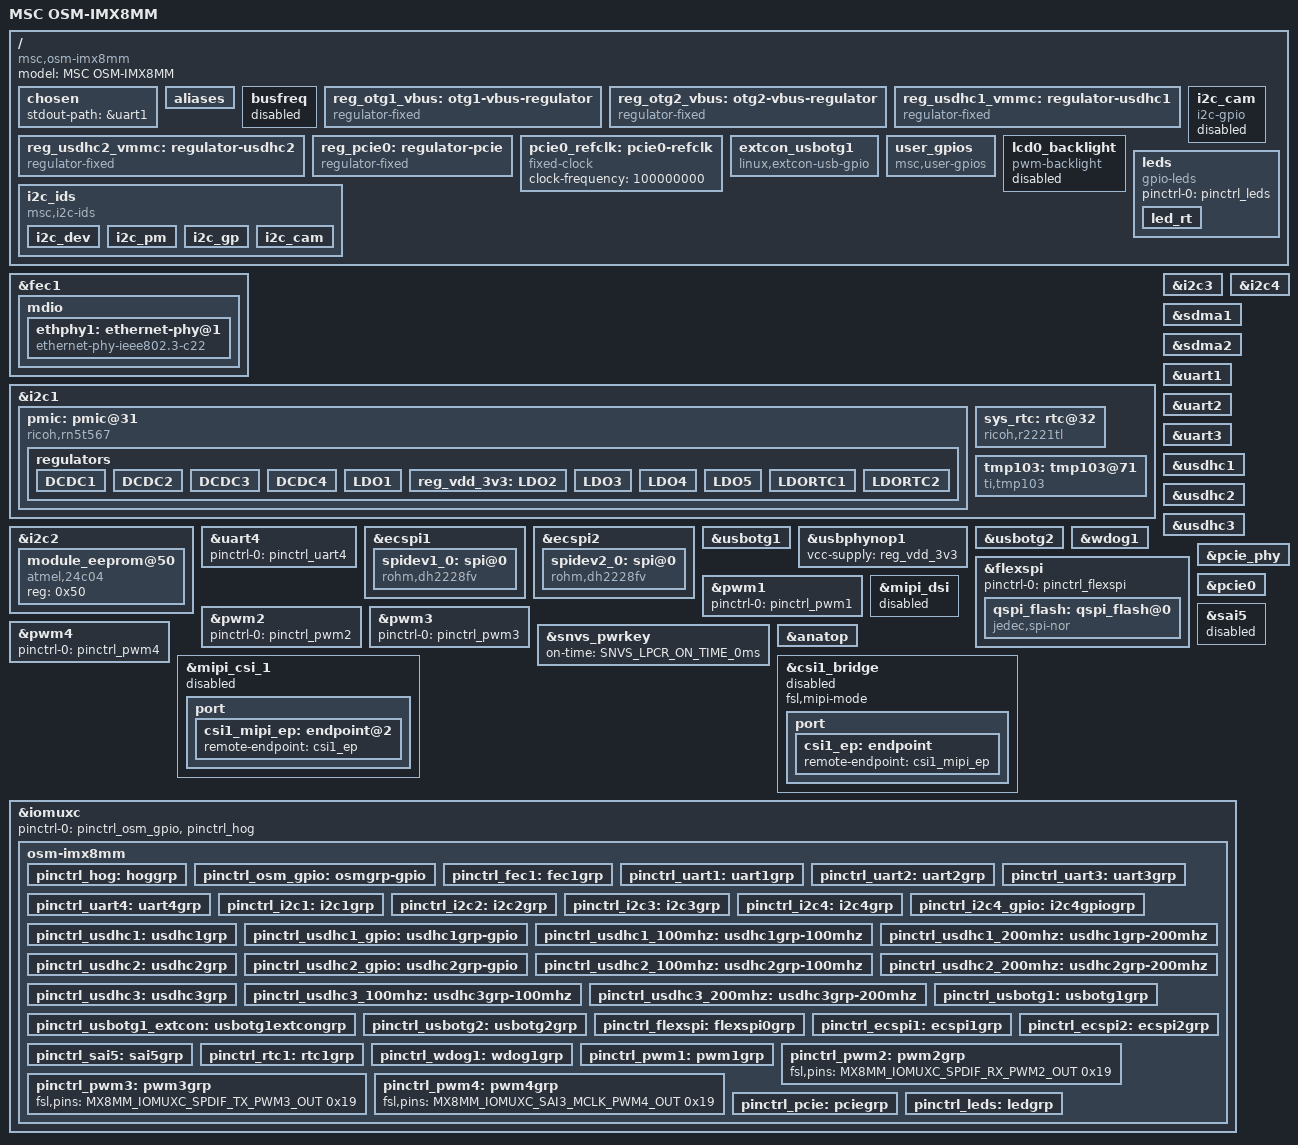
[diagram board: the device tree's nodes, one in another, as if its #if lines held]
/*
 * Copyright (C) 2022 Avnet Embedded GmbH
 *
 * This program is free software; you can redistribute it and/or
 * modify it under the terms of the GNU General Public License as
 * published by the Free Software Foundation version 2.
 *
 * This program is distributed "as is" WITHOUT ANY WARRANTY of any
 * kind, whether express or implied; without even the implied warranty
 * of MERCHANTABILITY or FITNESS FOR A PARTICULAR PURPOSE.  See the
 * GNU General Public License for more details.
 */

#include <dt-bindings/usb/pd.h>
#include "../../freescale/imx8mm.dtsi"
#include "dt-bindings/phy/phy-imx8-pcie.h"
#include <dt-bindings/net/ti-dp83867.h>
#include <dt-bindings/mfd/ricoh-rn5t618.h>
#include <dt-bindings/input/snvs_pwrkey.h>
#include <dt-bindings/thermal/thermal.h>

/ {
	model = "MSC OSM-IMX8MM";
	compatible = "msc,osm-imx8mm", "fsl,imx8mm";

	chosen {
		stdout-path = &uart1;
	};

	aliases {
		rtc0 = &sys_rtc;
		rtc1 = &snvs_rtc;
		ser0 = &uart1;
		ser1 = &uart3;
		ser2 = &uart2;
		ser3 = &uart4;
		i2c-dev = &i2c1;
		i2c-pm = &i2c2;
		i2c-gp = &i2c3;
		i2c-cam = &i2c4;
	};

	busfreq {
		status = "disabled";
	};

	reg_otg1_vbus: otg1-vbus-regulator {
		compatible = "regulator-fixed";
		regulator-name = "OTG1_VBUS";
		regulator-min-microvolt = <1800000>;
		regulator-max-microvolt = <1800000>;
		gpio = <&gpio1 12 GPIO_ACTIVE_HIGH>;
		enable-active-high;
		regulator-always-on;
	};

	reg_otg2_vbus: otg2-vbus-regulator {
		compatible = "regulator-fixed";
		regulator-name = "OTG2_VBUS";
		regulator-min-microvolt = <1800000>;
		regulator-max-microvolt = <1800000>;
		gpio = <&gpio1 14 GPIO_ACTIVE_HIGH>;
		enable-active-high;
		regulator-always-on;
	};

	reg_usdhc1_vmmc: regulator-usdhc1 {
		compatible = "regulator-fixed";
		regulator-name = "VSD1_3V3";
		regulator-min-microvolt = <3300000>;
		regulator-max-microvolt = <3300000>;
		gpio = <&gpio2 10 GPIO_ACTIVE_HIGH>;
		enable-active-high;
		startup-delay-us = <100>;
		u-boot,off-on-delay-us = <12000>;
	};

	reg_usdhc2_vmmc: regulator-usdhc2 {
		compatible = "regulator-fixed";
		regulator-name = "VSD2_3V3";
		regulator-min-microvolt = <3300000>;
		regulator-max-microvolt = <3300000>;
		gpio = <&gpio2 19 GPIO_ACTIVE_HIGH>;
		enable-active-high;
		startup-delay-us = <100>;
		u-boot,off-on-delay-us = <12000>;
	};

	reg_pcie0: regulator-pcie {
		compatible = "regulator-fixed";
		regulator-name = "PCIE_3V3";
		regulator-min-microvolt = <3300000>;
		regulator-max-microvolt = <3300000>;
		regulator-always-on;
	};

	pcie0_refclk: pcie0-refclk {
		compatible = "fixed-clock";
		#clock-cells = <0>;
		clock-frequency = <100000000>;
	};

	i2c_cam: i2c_cam {
		pinctrl-names = "default";
		pinctrl-0 = <&pinctrl_i2c4>, <&pinctrl_i2c4_gpio>;
		compatible = "i2c-gpio";
		#address-cells = <1>;
		#size-cells = <0>;
		sda-gpios = <&gpio5 21 (GPIO_ACTIVE_HIGH | GPIO_OPEN_DRAIN)>;
		scl-gpios = <&gpio5 20 (GPIO_ACTIVE_HIGH | GPIO_OPEN_DRAIN)>;
		i2c-gpio,delay-us = <2>;	/* ~100 kHz */
		status = "disabled";
	};

	extcon_usbotg1: extcon_usbotg1 {
		pinctrl-names = "default";
		pinctrl-0 = <&pinctrl_usbotg1_extcon>;
		compatible = "linux,extcon-usb-gpio";
		id-gpio = <&gpio1 10 GPIO_ACTIVE_HIGH>;
	};

	user_gpios {
		compatible = "msc,user-gpios";
		GPIO_A0-gpios = <&gpio4 25 GPIO_ACTIVE_HIGH>;
		GPIO_A1-gpios = <&gpio4 26 GPIO_ACTIVE_HIGH>;
		GPIO_A2-gpios = <&gpio4 21 GPIO_ACTIVE_HIGH>;
		GPIO_A3-gpios = <&gpio4 22 GPIO_ACTIVE_HIGH>;
		GPIO_A4-gpios = <&gpio1  0 GPIO_ACTIVE_HIGH>;
		GPIO_A5-gpios = <&gpio4 18 GPIO_ACTIVE_HIGH>;
		GPIO_A6-gpios = <&gpio4 20 GPIO_ACTIVE_HIGH>;
		GPIO_A7-gpios = <&gpio3 25 GPIO_ACTIVE_HIGH>;

		GPIO_B0-gpios = <&gpio3 20 GPIO_ACTIVE_HIGH>;
#if !defined(HAS_QSPI)
		GPIO_B1-gpios = <&gpio3  7 GPIO_ACTIVE_HIGH>;
		GPIO_B2-gpios = <&gpio3  6 GPIO_ACTIVE_HIGH>;
		GPIO_B3-gpios = <&gpio3  0 GPIO_ACTIVE_HIGH>;
		GPIO_B4-gpios = <&gpio3  1 GPIO_ACTIVE_HIGH>;
		GPIO_B5-gpios = <&gpio3  8 GPIO_ACTIVE_HIGH>;
		GPIO_B6-gpios = <&gpio3  9 GPIO_ACTIVE_HIGH>;
#endif
		GPIO_B7-gpios = <&gpio4  3 GPIO_ACTIVE_HIGH>;

		GPIO_C0-gpios = <&gpio4  4 GPIO_ACTIVE_HIGH>;
		GPIO_C1-gpios = <&gpio4  5 GPIO_ACTIVE_HIGH>;
		GPIO_C2-gpios = <&gpio4  9 GPIO_ACTIVE_HIGH>;
		GPIO_C3-gpios = <&gpio4 13 GPIO_ACTIVE_HIGH>;
		GPIO_C4-gpios = <&gpio1  1 GPIO_ACTIVE_HIGH>; /* used as panel enable  */
/*		GPIO_C5-gpios = <&gpio1  5 GPIO_ACTIVE_HIGH>; used as backlight enable */

		GPIO_D0-gpios = <&gpio4  6 GPIO_ACTIVE_HIGH>;
		GPIO_D1-gpios = <&gpio4  7 GPIO_ACTIVE_HIGH>;
		GPIO_D2-gpios = <&gpio4 14 GPIO_ACTIVE_HIGH>;
		GPIO_D3-gpios = <&gpio4 15 GPIO_ACTIVE_HIGH>;
		GPIO_D4-gpios = <&gpio4 19 GPIO_ACTIVE_HIGH>;
		GPIO_D5-gpios = <&gpio4  8 GPIO_ACTIVE_HIGH>;
		GPIO_D6-gpios = <&gpio4 17 GPIO_ACTIVE_HIGH>;
		GPIO_D7-gpios = <&gpio4 16 GPIO_ACTIVE_HIGH>;
	};

	lcd0_backlight: lcd0_backlight {
		compatible = "pwm-backlight";
		pwms = <&pwm1 0 1000000 0>;
		brightness-levels = <
			  0   1   2   3   4   5   6   7   8   9
			 10  11  12  13  14  15  16  17  18  19
			 20  21  22  23  24  25  26  27  28  29
			 30  31  32  33  34  35  36  37  38  39
			 40  41  42  43  44  45  46  47  48  49
			 50  51  52  53  54  55  56  57  58  59
			 60  61  62  63  64  65  66  67  68  69
			 70  71  72  73  74  75  76  77  78  79
			 80  81  82  83  84  85  86  87  88  89
			 90  91  92  93  94  95  96  97  98  99
			100 101 102 103 104 105 106 107 108 109
			110 111 112 113 114 115 116 117 118 119
			120 121 122 123 124 125 126 127 128 129
			130 131 132 133 134 135 136 137 138 139
			140 141 142 143 144 145 146 147 148 149
			150 151 152 153 154 155 156 157 158 159
			160 161 162 163 164 165 166 167 168 169
			170 171 172 173 174 175 176 177 178 179
			180 181 182 183 184 185 186 187 188 189
			190 191 192 193 194 195 196 197 198 199
			200 201 202 203 204 205 206 207 208 209
			210 211 212 213 214 215 216 217 218 219
			220 221 222 223 224 225 226 227 228 229
			230 231 232 233 234 235 236 237 238 239
			240 241 242 243 244 245 246 247 248 249
			250 251 252 253 254 255
		>;
		default-brightness-level = <255>;
		enable-gpios = <&gpio1 5 GPIO_ACTIVE_HIGH>;		/* GPIO_C_5*/
		status = "disabled";
	};

	i2c_ids {
		compatible = "msc,i2c-ids";
		i2c_dev {
			label = "dev";
			bus = <&i2c1>;
		};
		i2c_pm {
			label = "pm";
			bus = <&i2c2>;
		};
		i2c_gp {
			label = "gp";
			bus = <&i2c3>;
		};
		i2c_cam {
			label = "cam";
			bus = <&i2c4>;
		};
	};
	leds {
		compatible = "gpio-leds";
		pinctrl-names = "default";
		pinctrl-0 = <&pinctrl_leds>;

		led_rt {
			label = "LED_RT";
			gpios = <&gpio4 27 GPIO_ACTIVE_HIGH>;
			linux,default-trigger = "heartbeat";
		};
	};

};

&fec1 {
	pinctrl-names = "default";
	pinctrl-0 = <&pinctrl_fec1>;
	phy-mode = "rgmii-id";
	phy-handle = <&ethphy1>;
	fsl,magic-packet;
	status = "okay";

	mdio {
		#address-cells = <1>;
		#size-cells = <0>;

		ethphy1: ethernet-phy@1 {
			compatible = "ethernet-phy-ieee802.3-c22";
			reg = <1>;
			eee-broken-1000t;
			ti,rx-internal-delay = <DP83867_RGMIIDCTL_2_25_NS>;
			ti,tx-internal-delay = <DP83867_RGMIIDCTL_2_75_NS>;
			ti,fifo-depth = <DP83867_PHYCR_FIFO_DEPTH_4_B_NIB>;
			ti,led-2-sel = <MII_DP83867_LEDCR1_LED_SEL_LE_RX_TX_ACT>;
			ti,led-1-sel = <MII_DP83867_LEDCR1_LED_SEL_1000BT_LE>;
			ti,led-0-sel = <MII_DP83867_LEDCR1_LED_SEL_100BTX_LE>;
			ti,led-gpio-polarity-active-high;
			ti,led-2-polarity-active-high;
			ti,led-1-polarity-active-high;
			ti,led-0-polarity-active-high;
			ti,clk-output-sel = <DP83867_CLK_O_SEL_OFF>;
		};
	};
};

/* I2C_DEV */
&i2c1 {
	pinctrl-names = "default";
	pinctrl-0 = <&pinctrl_i2c1>;
	clock-frequency = <400000>;
	status = "okay";

	pmic: pmic@31 {
		compatible = "ricoh,rn5t567";
		reg = <0x31>;
		pmic-id = <0>;
		sleep-sequence = /bits/ 8 <
				0x16	0x2b
				0x17	0x49
				0x1b	0x2b
				0x1c	0x67
				0x1f	0x0b
				0x32	0x03
				0x30	0x03
			>;
		repower-time = <REPWRTIME_1000MS>;

		regulators {
			DCDC1 {
				regulator-name = "VCC_SOC";
				regulator-always-on;
				regulator-min-microvolt = <900000>;
				regulator-max-microvolt = <900000>;
			};
			DCDC2 {
				regulator-name = "VCC_ARM";
				regulator-always-on;
				regulator-min-microvolt = <950000>;
				regulator-max-microvolt = <950000>;
			};
			DCDC3 {
				regulator-name = "VCC_DRAM_1V1";
				regulator-always-on;
				regulator-min-microvolt = <1100000>;
				regulator-max-microvolt = <1100000>;
			};
			DCDC4 {
				regulator-name = "VCC_1V8_PMIC";
				regulator-always-on;
				regulator-min-microvolt = <1800000>;
				regulator-max-microvolt = <1800000>;
			};
			LDO1 {
				regulator-name = "VCC_2V5";
				regulator-always-on;
				regulator-min-microvolt = <2500000>;
				regulator-max-microvolt = <2500000>;
			};
			reg_vdd_3v3: LDO2 {
				regulator-name = "VCC_3V3";
				regulator-always-on;
				regulator-min-microvolt = <3300000>;
				regulator-max-microvolt = <3300000>;
			};
			LDO3 {
				regulator-name = "VCC_3V3_2";
				regulator-always-on;
				regulator-min-microvolt = <3300000>;
				regulator-max-microvolt = <3300000>;
			};
			LDO4 {
				regulator-name = "VCC_LDO4_1V8";
				regulator-always-on;
				regulator-min-microvolt = <1800000>;
				regulator-max-microvolt = <1800000>;
			};
			LDO5 {
				regulator-name = "VCC_1V2";
				regulator-always-on;
				regulator-min-microvolt = <1200000>;
				regulator-max-microvolt = <1200000>;
			};
			LDORTC1 {
				regulator-name = "VCC_SNVS_1V8";
				regulator-always-on;
				regulator-min-microvolt = <1800000>;
				regulator-max-microvolt = <1800000>;
			};
			LDORTC2 {
				regulator-name = "VCC_PM1_SNVS_3V3";
				regulator-always-on;
				regulator-min-microvolt = <3300000>;
				regulator-max-microvolt = <3300000>;
			};
		};
	};

	sys_rtc: rtc@32 {
		compatible = "ricoh,r2221tl";
		pinctrl-names = "default";
		pinctrl-0 = <&pinctrl_rtc1>;
		reg = <0x32>;
	};

	tmp103: tmp103@71 {
		compatible = "ti,tmp103";
		reg = <0x71>;
		label = "BOARD_TEMP";
	};

};

/* I2C_A */
&i2c2 {
	clock-frequency = <400000>;
	pinctrl-names = "default";
	pinctrl-0 = <&pinctrl_i2c2>;
	status = "okay";

	module_eeprom@50 {
		compatible = "atmel,24c04";
		reg = <0x50>;
	};
};

/* I2C_B */
&i2c3 {
	clock-frequency = <100000>;
	pinctrl-names = "default";
	pinctrl-0 = <&pinctrl_i2c3>;
	status = "okay";

};

/* I2C_CAM */
&i2c4 {
	clock-frequency = <100000>;
	pinctrl-names = "default";
	pinctrl-0 = <&pinctrl_i2c4>;
	status = "okay";
};

&sdma1 {
	status = "okay";
};

&sdma2 {
	status = "okay";
};

/* UART_A */
&uart1 {
	pinctrl-names = "default";
	pinctrl-0 = <&pinctrl_uart1>;
	fsl,uart-has-rtscts;
	cts-gpios = <&gpio4 23 GPIO_ACTIVE_LOW>;
	rts-gpios = <&gpio4 24 GPIO_ACTIVE_LOW>;
	status = "okay";
};

/* UART_B */
&uart2 {
	pinctrl-names = "default";
	pinctrl-0 = <&pinctrl_uart2>;
	fsl,uart-has-rtscts;
	cts-gpios = <&gpio4 29 GPIO_ACTIVE_LOW>;
	rts-gpios = <&gpio4 30 GPIO_ACTIVE_LOW>;
	status = "okay";
};

/* UART_C */
&uart3 {
	pinctrl-names = "default";
	pinctrl-0 = <&pinctrl_uart3>;
	assigned-clocks = <&clk IMX8MM_CLK_UART3>;
	assigned-clock-parents = <&clk IMX8MM_SYS_PLL1_80M>;
	status = "okay";
};

/* UART_D */
&uart4 {
	pinctrl-names = "default";
	pinctrl-0 = <&pinctrl_uart4>;
	status = "okay";
};

/* SPI_A */
&ecspi1 {
	#address-cells = <1>;
	#size-cells = <0>;
	pinctrl-names = "default";
	pinctrl-0 = <&pinctrl_ecspi1>;
	fsl,spi-num-chipselects = <1>;
	cs-gpios = <&gpio5 9 GPIO_ACTIVE_LOW>;
	status = "okay";

	spidev1_0: spi@0 {
		compatible = "rohm,dh2228fv";
		reg = <0>;
		spi-max-frequency = <500000>;
	};

};
/* SPI_B */
&ecspi2 {
	#address-cells = <1>;
	#size-cells = <0>;
	pinctrl-names = "default";
	pinctrl-0 = <&pinctrl_ecspi2>;
	fsl,spi-num-chipselects = <1>;
	cs-gpios = <&gpio5 13 GPIO_ACTIVE_LOW>;
	status = "okay";

	spidev2_0: spi@0 {
		compatible = "rohm,dh2228fv";
		reg = <0>;
		spi-max-frequency = <500000>;
	};
};

/* SDIO_B */
&usdhc1 {
	assigned-clocks = <&clk IMX8MM_CLK_USDHC1>;
	assigned-clock-rates = <200000000>;
	pinctrl-names = "default", "state_100mhz", "state_200mhz";
	pinctrl-0 = <&pinctrl_usdhc1>, <&pinctrl_usdhc1_gpio>;
	pinctrl-1 = <&pinctrl_usdhc1_100mhz>, <&pinctrl_usdhc1_gpio>;
	pinctrl-2 = <&pinctrl_usdhc1_200mhz>, <&pinctrl_usdhc1_gpio>;
	cd-gpios = <&gpio1  6 GPIO_ACTIVE_LOW>;
	wp-gpios = <&gpio1  7 GPIO_ACTIVE_HIGH>;
	vmmc-supply = <&reg_usdhc1_vmmc>;
	bus-width = <8>;
	status = "okay";
};

/* SDIO_A */
&usdhc2 {
	assigned-clocks = <&clk IMX8MM_CLK_USDHC2>;
	assigned-clock-rates = <200000000>;
	pinctrl-names = "default", "state_100mhz", "state_200mhz";
	pinctrl-0 = <&pinctrl_usdhc2>, <&pinctrl_usdhc2_gpio>;
	pinctrl-1 = <&pinctrl_usdhc2_100mhz>, <&pinctrl_usdhc2_gpio>;
	pinctrl-2 = <&pinctrl_usdhc2_200mhz>, <&pinctrl_usdhc2_gpio>;
	cd-gpios = <&gpio2 12 GPIO_ACTIVE_LOW>;
	wp-gpios = <&gpio2 20 GPIO_ACTIVE_HIGH>;
	vmmc-supply = <&reg_usdhc2_vmmc>;
	bus-width = <4>;
	status = "okay";
};

/* eMMC */
&usdhc3 {
	assigned-clocks = <&clk IMX8MM_CLK_USDHC3_ROOT>;
	assigned-clock-rates = <400000000>;
	pinctrl-names = "default", "state_100mhz", "state_200mhz";
	pinctrl-0 = <&pinctrl_usdhc3>;
	pinctrl-1 = <&pinctrl_usdhc3_100mhz>;
	pinctrl-2 = <&pinctrl_usdhc3_200mhz>;
	bus-width = <8>;
	non-removable;
	status = "okay";
};

&usbotg1 {
	pinctrl-names = "default";
	pinctrl-0 = <&pinctrl_usbotg1>;
	vbus-supply = <&reg_otg1_vbus>;
	dr_mode = "host";
	disable-over-current;
	extcon = <0>, <&extcon_usbotg1>;
	status = "okay";
};

&usbphynop1 {
	vcc-supply = <&reg_vdd_3v3>;
};

&usbotg2 {
	pinctrl-names = "default";
	pinctrl-0 = <&pinctrl_usbotg2>;
	vbus-supply = <&reg_otg2_vbus>;
	disable-over-current;
	dr_mode = "host";
	status = "okay";
};

&usbphynop1 {
	vcc-supply = <&reg_vdd_3v3>;
};

&wdog1 {
	pinctrl-names = "default";
	pinctrl-0 = <&pinctrl_wdog1>;
	fsl,ext-reset-output;
	status = "okay";
};

#ifdef HAS_QSPI
/* qspi */
&flexspi {
	pinctrl-names = "default";
	pinctrl-0 = <&pinctrl_flexspi>;
	status = "okay";

	qspi_flash: qspi_flash@0 {
		reg = <0>;
		#address-cells = <1>;
		#size-cells = <1>;
		compatible = "jedec,spi-nor";
		spi-max-frequency = <30000000>;
		spi-tx-bus-width = <4>;
		spi-rx-bus-width = <4>;
	};
};
#endif

&pwm1 {
	pinctrl-names = "default";
	pinctrl-0 = <&pinctrl_pwm1>;
	status = "okay";
};

&pwm2 {
	pinctrl-names = "default";
	pinctrl-0 = <&pinctrl_pwm2>;
	status = "okay";
};

&pwm3 {
	pinctrl-names = "default";
	pinctrl-0 = <&pinctrl_pwm3>;
	status = "okay";
};

&pwm4 {
	pinctrl-names = "default";
	pinctrl-0 = <&pinctrl_pwm4>;
	status = "okay";
};

&pcie_phy {
	/* IMX8_PCIE_REFCLK_PAD_INPUT  -> ext clock */
	/* IMX8_PCIE_REFCLK_PAD_OUTPUT -> int clock */
	fsl,refclk-pad-mode = <IMX8_PCIE_REFCLK_PAD_OUTPUT>;
	fsl,tx-deemph-gen1 = <0x2d>;
	fsl,tx-deemph-gen2 = <0xf>;
	clocks = <&pcie0_refclk>;
	status = "okay";
};

&pcie0 {
	pinctrl-names = "default";
	pinctrl-0 = <&pinctrl_pcie>;
	reset-gpio = <&gpio4 1 GPIO_ACTIVE_LOW>;
	clocks = <&clk IMX8MM_CLK_PCIE1_ROOT>,
		 <&clk IMX8MM_CLK_PCIE1_AUX>,
		 <&pcie0_refclk>;
	clock-names = "pcie", "pcie_aux", "pcie_bus";
	assigned-clocks = <&clk IMX8MM_CLK_PCIE1_AUX>,
			  <&clk IMX8MM_CLK_PCIE1_CTRL>;
	assigned-clock-rates = <10000000>, <250000000>;
	assigned-clock-parents = <&clk IMX8MM_SYS_PLL2_50M>,
				 <&clk IMX8MM_SYS_PLL2_250M>;
	vpcie-supply = <&reg_pcie0>;
	status = "okay";
};

&mipi_dsi {
	status = "disabled";
};

&sai5 {
	pinctrl-names = "default";
	pinctrl-0 = <&pinctrl_sai5>;
	assigned-clocks = <&clk IMX8MM_CLK_SAI5>;
	assigned-clock-parents = <&clk IMX8MM_AUDIO_PLL1_OUT>;
	assigned-clock-rates = <49152000>;
	clocks = <&clk IMX8MM_CLK_SAI5_IPG>, <&clk IMX8MM_CLK_DUMMY>,
		<&clk IMX8MM_CLK_SAI5_ROOT>, <&clk IMX8MM_CLK_DUMMY>,
		<&clk IMX8MM_CLK_DUMMY>, <&clk IMX8MM_AUDIO_PLL1_OUT>,
		<&clk IMX8MM_AUDIO_PLL2_OUT>;
	clock-names = "bus", "mclk0", "mclk1", "mclk2", "mclk3", "pll8k", "pll11k";
	status = "disabled";
};

&snvs_pwrkey {
	on-time = <SNVS_LPCR_ON_TIME_0ms>;
	status = "okay";
};

&anatop {
	/* video-pll1-ss,enable; */
	video-pll1-ss,ffin_MHz = <24>;
	video-pll1-ss,mf_kHz = <30>;
	video-pll1-ss,mr = <VIDEO_PLL1_SPREAD_DEPTH_0_5_PERCENT>;
};


&mipi_csi_1 {
	#address-cells = <1>;
	#size-cells = <0>;
	status = "disabled";
	port {
		csi1_mipi_ep: endpoint@2 {
			remote-endpoint = <&csi1_ep>;
		};
	};
};

&csi1_bridge {
	fsl,mipi-mode;
	status = "disabled";
	port {
		csi1_ep: endpoint {
			remote-endpoint = <&csi1_mipi_ep>;
		};
	};
};

&iomuxc {
	pinctrl-names = "default";
	pinctrl-0 = <&pinctrl_osm_gpio>, <&pinctrl_hog>;

	osm-imx8mm {
		pinctrl_hog: hoggrp {
			fsl,pins = <
				MX8MM_IOMUXC_UART2_RXD_GPIO5_IO24	0x40000019	/* BOOT_SEL0# */
				MX8MM_IOMUXC_UART2_TXD_GPIO5_IO25	0x40000019	/* BOOT_SEL1# */
			>;
		};

		pinctrl_osm_gpio: osmgrp-gpio {
			fsl,pins = <
				/* GPIO_A */
				MX8MM_IOMUXC_SAI2_TXC_GPIO4_IO25	0x40000019	/* GPIO A 0 */
				MX8MM_IOMUXC_SAI2_TXD0_GPIO4_IO26	0x40000019	/* GPIO A 1 */
				MX8MM_IOMUXC_SAI2_RXFS_GPIO4_IO21	0x40000019	/* GPIO A 2 */
				MX8MM_IOMUXC_SAI2_RXC_GPIO4_IO22	0x40000019	/* GPIO A 3 */
				MX8MM_IOMUXC_GPIO1_IO00_GPIO1_IO0	0x40000019	/* GPIO A 4 */
				MX8MM_IOMUXC_SAI1_TXD6_GPIO4_IO18	0x40000019	/* GPIO A 5 */
				MX8MM_IOMUXC_SAI1_MCLK_GPIO4_IO20	0x40000019	/* GPIO A 6 */
				MX8MM_IOMUXC_SAI5_MCLK_GPIO3_IO25	0x40000019	/* GPIO A 7 */

				/* GPIO_B */
				MX8MM_IOMUXC_SAI5_RXC_GPIO3_IO20	0x40000019	/* GPIO B 0 */
#if !defined(HAS_QSPI)
				MX8MM_IOMUXC_NAND_DATA01_GPIO3_IO7	0x40000019	/* GPIO B 1 - QSPI_DATA 1 */
				MX8MM_IOMUXC_NAND_DATA00_GPIO3_IO6	0x40000019	/* GPIO B 2 - QSPI_DATA 0 */
				MX8MM_IOMUXC_NAND_ALE_GPIO3_IO0		0x40000019	/* GPIO B 3 - QSPI_CLK    */
				MX8MM_IOMUXC_NAND_CE0_B_GPIO3_IO1	0x40000019	/* GPIO B 4 - QSPI_CS0#   */
				MX8MM_IOMUXC_NAND_DATA02_GPIO3_IO8	0x40000019	/* GPIO B 5 - QSPI_DATA 2 */
				MX8MM_IOMUXC_NAND_DATA03_GPIO3_IO9	0x40000019	/* GPIO B 6 - QSPI_DATA 3 */
#endif
				MX8MM_IOMUXC_SAI1_RXD1_GPIO4_IO3        0x40000019      /* GPIO B 7 */

				/* GPIO_C */
				MX8MM_IOMUXC_SAI1_RXD2_GPIO4_IO4	0x40000019	/* GPIO C 0 */
				MX8MM_IOMUXC_SAI1_RXD3_GPIO4_IO5	0x40000019	/* GPIO C 1 */
				MX8MM_IOMUXC_SAI1_RXD7_GPIO4_IO9	0x40000019	/* GPIO C 2 */
				MX8MM_IOMUXC_SAI1_TXD1_GPIO4_IO13	0x40000019	/* GPIO C 3 */
				MX8MM_IOMUXC_GPIO1_IO01_GPIO1_IO1	0x40000019	/* GPIO C 4 DISP_VDD_EN */
				MX8MM_IOMUXC_GPIO1_IO05_GPIO1_IO5	0x40000019	/* GPIO C 5 DISP_BL_EN  */

				/* GPIO_D */
				MX8MM_IOMUXC_SAI1_RXD4_GPIO4_IO6	0x40000019	/* GPIO D 0 */
				MX8MM_IOMUXC_SAI1_RXD5_GPIO4_IO7	0x40000019	/* GPIO D 1 */
				MX8MM_IOMUXC_SAI1_TXD2_GPIO4_IO14	0x40000019	/* GPIO D 2 */
				MX8MM_IOMUXC_SAI1_TXD3_GPIO4_IO15	0x40000019	/* GPIO D 3 */
				MX8MM_IOMUXC_SAI1_TXD7_GPIO4_IO19	0x40000019	/* GPIO D 4 */
				MX8MM_IOMUXC_SAI1_RXD6_GPIO4_IO8	0x40000019	/* GPIO D 5 */
				MX8MM_IOMUXC_SAI1_TXD5_GPIO4_IO17	0x40000019	/* GPIO D 6 */
				MX8MM_IOMUXC_SAI1_TXD4_GPIO4_IO16	0x40000019	/* GPIO D 7 */
			>;
		};

		pinctrl_fec1: fec1grp {
			fsl,pins = <
				MX8MM_IOMUXC_ENET_MDC_ENET1_MDC			0x02	/* GBE_MDIO_CLK */
				MX8MM_IOMUXC_ENET_MDIO_ENET1_MDIO		0x02	/* GBE_MDIO_DATA */
				MX8MM_IOMUXC_ENET_TX_CTL_ENET1_RGMII_TX_CTL	0x16	/* RGMII_TXEN */
				MX8MM_IOMUXC_ENET_TXC_ENET1_RGMII_TXC		0x16	/* RGMII_TCLK */
				MX8MM_IOMUXC_ENET_TD0_ENET1_RGMII_TD0		0x16	/* RGMII_TXD0 */
				MX8MM_IOMUXC_ENET_TD1_ENET1_RGMII_TD1		0x16	/* RGMII_TXD1 */
				MX8MM_IOMUXC_ENET_TD2_ENET1_RGMII_TD2		0x16	/* RGMII_TXD2 */
				MX8MM_IOMUXC_ENET_TD3_ENET1_RGMII_TD3		0x16	/* RGMII_TXD3 */
				MX8MM_IOMUXC_ENET_RX_CTL_ENET1_RGMII_RX_CTL	0x90	/* RGMII_RCNT */
				MX8MM_IOMUXC_ENET_RXC_ENET1_RGMII_RXC		0x90	/* RGMII_RCLK */
				MX8MM_IOMUXC_ENET_RD0_ENET1_RGMII_RD0		0x90	/* RGMII_RXD0 */
				MX8MM_IOMUXC_ENET_RD1_ENET1_RGMII_RD1		0x90	/* RGMII_RXD1 */
				MX8MM_IOMUXC_ENET_RD2_ENET1_RGMII_RD2		0x90	/* RGMII_RXD2 */
				MX8MM_IOMUXC_ENET_RD3_ENET1_RGMII_RD3		0x90	/* RGMII_RXD3 */
			>;
		};

		/* UART_A */
		pinctrl_uart1: uart1grp {
			fsl,pins = <
				MX8MM_IOMUXC_UART1_RXD_UART1_DCE_RX		0x49	/* SER_A_RX  */
				MX8MM_IOMUXC_UART1_TXD_UART1_DCE_TX		0x49	/* SER_A_TX  */
				MX8MM_IOMUXC_SAI2_RXD0_GPIO4_IO23		0x19	/* SER_A_CTS */
				MX8MM_IOMUXC_SAI2_TXFS_GPIO4_IO24		0x19	/* SER_A_RTS */
			>;
		};

		/* UART_B */
		pinctrl_uart2: uart2grp {
			fsl,pins = <
				MX8MM_IOMUXC_SAI3_TXFS_UART2_DCE_RX		0x49	/* SER_B_RX  */
				MX8MM_IOMUXC_SAI3_TXC_UART2_DCE_TX		0x49	/* SER_B_TX  */
				MX8MM_IOMUXC_SAI3_RXC_GPIO4_IO29		0x19	/* SER_B_CTS */
				MX8MM_IOMUXC_SAI3_RXD_GPIO4_IO30		0x19	/* SER_B_RTS */
			>;
		};

		/* UART_C */
		pinctrl_uart3: uart3grp {
			fsl,pins = <
				MX8MM_IOMUXC_UART3_RXD_UART3_DCE_RX		0x49	/* SER_C_RX */
				MX8MM_IOMUXC_UART3_TXD_UART3_DCE_TX		0x49	/* SER_C_TX */
			>;
		};

		/* UART_D */
		pinctrl_uart4: uart4grp {
			fsl,pins = <
				MX8MM_IOMUXC_UART4_RXD_UART4_DCE_RX		0x49	/* SER_D_RX */
				MX8MM_IOMUXC_UART4_TXD_UART4_DCE_TX		0x49	/* SER_D_TX */
			>;
		};

		/* I2C_DEV */
		pinctrl_i2c1: i2c1grp {
			fsl,pins = <
				MX8MM_IOMUXC_I2C1_SCL_I2C1_SCL		0x400001c3	/* I2C_DEV_SCL */
				MX8MM_IOMUXC_I2C1_SDA_I2C1_SDA		0x400001c3	/* I2C_DEV_SDA */
			>;
		};

		/* I2C_PM */
		pinctrl_i2c2: i2c2grp {
			fsl,pins = <
				MX8MM_IOMUXC_I2C2_SCL_I2C2_SCL		0x400001c3	/* I2C_PM_SCL */
				MX8MM_IOMUXC_I2C2_SDA_I2C2_SDA		0x400001c3	/* I2C_PM_SDA */
			>;
		};

		/* I2C_GP */
		pinctrl_i2c3: i2c3grp {
			fsl,pins = <
				MX8MM_IOMUXC_I2C3_SCL_I2C3_SCL		0x400001c3	/* I2C_GP_SCL */
				MX8MM_IOMUXC_I2C3_SDA_I2C3_SDA		0x400001c3	/* I2C_GP_SDA */

			>;
		};

		/* I2C4 */
		pinctrl_i2c4: i2c4grp {
			fsl,pins = <
				MX8MM_IOMUXC_I2C4_SCL_I2C4_SCL		0x400001c3	/* I2C_LCD_SCL */
				MX8MM_IOMUXC_I2C4_SDA_I2C4_SDA		0x400001c3	/* I2C_LCD_SDA */
			>;
		};

		/* I2C4_GPIO */
		pinctrl_i2c4_gpio: i2c4gpiogrp {
			fsl,pins = <
				MX8MM_IOMUXC_I2C4_SCL_GPIO5_IO20	0x40000116	/* I2C_CAM_SCL, linux-gpio-id=148 */
				MX8MM_IOMUXC_I2C4_SDA_GPIO5_IO21	0x40000116	/* I2C_CAM_SDA, linux-gpio-id=149 */
			>;
		};

		/* SDIO_B */
		pinctrl_usdhc1: usdhc1grp {
			fsl,pins = <
				MX8MM_IOMUXC_SD1_CLK_USDHC1_CLK			0x92	/* SD1_CLK,   SDIO_B_CK    */
				MX8MM_IOMUXC_SD1_CMD_USDHC1_CMD			0x92	/* SD1_CMD,   SDIO_B_CMD   */
				MX8MM_IOMUXC_SD1_DATA0_USDHC1_DATA0		0x92	/* SD1_DATA0, SDIO_B_DATA0 */
				MX8MM_IOMUXC_SD1_DATA1_USDHC1_DATA1		0x92	/* SD1_DATA1, SDIO_B_DATA1 */
				MX8MM_IOMUXC_SD1_DATA2_USDHC1_DATA2		0x92	/* SD1_DATA2, SDIO_B_DATA2 */
				MX8MM_IOMUXC_SD1_DATA3_USDHC1_DATA3		0x92	/* SD1_DATA3, SDIO_B_DATA3 */
				MX8MM_IOMUXC_SD1_DATA4_USDHC1_DATA4		0x92	/* SD1_DATA4, SDIO_B_DATA4 */
				MX8MM_IOMUXC_SD1_DATA5_USDHC1_DATA5		0x92	/* SD1_DATA5, SDIO_B_DATA5 */
				MX8MM_IOMUXC_SD1_DATA6_USDHC1_DATA6		0x92	/* SD1_DATA6, SDIO_B_DATA6 */
				MX8MM_IOMUXC_SD1_DATA7_USDHC1_DATA7		0x92	/* SD1_DATA7, SDIO_B_DATA7 */
			>;
		};

		pinctrl_usdhc1_gpio: usdhc1grp-gpio {
			fsl,pins = <
				MX8MM_IOMUXC_GPIO1_IO06_GPIO1_IO6		0x41	/* SD1_CD_B, SDIO_B_CD, linux-gpio-id=6  */
				MX8MM_IOMUXC_GPIO1_IO07_GPIO1_IO7		0x41	/* SD1_WP, SDIO_B_WP,   linux-gpio-id=7  */
				MX8MM_IOMUXC_SD1_RESET_B_GPIO2_IO10		0x41	/* SDIO_B_PWR_EN,       linux-gpio-id=42 */
				MX8MM_IOMUXC_GPIO1_IO03_USDHC1_VSELECT		0x1d0	/* USDHC1_VSELECT */
			>;
		};

		pinctrl_usdhc1_100mhz: usdhc1grp-100mhz {
			fsl,pins = <
				MX8MM_IOMUXC_SD1_CLK_USDHC1_CLK			0x94	/* SD1_CLK,   SDIO_B_CK    */
				MX8MM_IOMUXC_SD1_CMD_USDHC1_CMD			0x94	/* SD1_CMD,   SDIO_B_CMD   */
				MX8MM_IOMUXC_SD1_DATA0_USDHC1_DATA0		0x94	/* SD1_DATA0, SDIO_B_DATA0 */
				MX8MM_IOMUXC_SD1_DATA1_USDHC1_DATA1		0x94	/* SD1_DATA1, SDIO_B_DATA1 */
				MX8MM_IOMUXC_SD1_DATA2_USDHC1_DATA2		0x94	/* SD1_DATA2, SDIO_B_DATA2 */
				MX8MM_IOMUXC_SD1_DATA3_USDHC1_DATA3		0x94	/* SD1_DATA3, SDIO_B_DATA3 */
				MX8MM_IOMUXC_SD1_DATA4_USDHC1_DATA4		0x94	/* SD1_DATA4, SDIO_B_DATA4 */
				MX8MM_IOMUXC_SD1_DATA5_USDHC1_DATA5		0x94	/* SD1_DATA5, SDIO_B_DATA5 */
				MX8MM_IOMUXC_SD1_DATA6_USDHC1_DATA6		0x94	/* SD1_DATA6, SDIO_B_DATA6 */
				MX8MM_IOMUXC_SD1_DATA7_USDHC1_DATA7		0x94	/* SD1_DATA7, SDIO_B_DATA7 */
			>;
		};

		pinctrl_usdhc1_200mhz: usdhc1grp-200mhz {
			fsl,pins = <
				MX8MM_IOMUXC_SD1_CLK_USDHC1_CLK			0x96	/* SD1_CLK,   SDIO_B_CK    */
				MX8MM_IOMUXC_SD1_CMD_USDHC1_CMD			0x96	/* SD1_CMD,   SDIO_B_CMD   */
				MX8MM_IOMUXC_SD1_DATA0_USDHC1_DATA0		0x96	/* SD1_DATA0, SDIO_B_DATA0 */
				MX8MM_IOMUXC_SD1_DATA1_USDHC1_DATA1		0x96	/* SD1_DATA1, SDIO_B_DATA1 */
				MX8MM_IOMUXC_SD1_DATA2_USDHC1_DATA2		0x96	/* SD1_DATA2, SDIO_B_DATA2 */
				MX8MM_IOMUXC_SD1_DATA3_USDHC1_DATA3		0x96	/* SD1_DATA3, SDIO_B_DATA3 */
				MX8MM_IOMUXC_SD1_DATA4_USDHC1_DATA4		0x96	/* SD1_DATA4, SDIO_B_DATA4 */
				MX8MM_IOMUXC_SD1_DATA5_USDHC1_DATA5		0x96	/* SD1_DATA5, SDIO_B_DATA5 */
				MX8MM_IOMUXC_SD1_DATA6_USDHC1_DATA6		0x96	/* SD1_DATA6, SDIO_B_DATA6 */
				MX8MM_IOMUXC_SD1_DATA7_USDHC1_DATA7		0x96	/* SD1_DATA7, SDIO_B_DATA7 */
			>;
		};

		/* SDIO_A */
		pinctrl_usdhc2: usdhc2grp {
			fsl,pins = <
				MX8MM_IOMUXC_SD2_CLK_USDHC2_CLK			0x92	/* SD2_CLK,   SDIO_A_CK    */
				MX8MM_IOMUXC_SD2_CMD_USDHC2_CMD			0x92	/* SD2_CMD,   SDIO_A_CMD   */
				MX8MM_IOMUXC_SD2_DATA0_USDHC2_DATA0		0x92	/* SD2_DATA0, SDIO_A_DATA0 */
				MX8MM_IOMUXC_SD2_DATA1_USDHC2_DATA1		0x92	/* SD2_DATA1, SDIO_A_DATA1 */
				MX8MM_IOMUXC_SD2_DATA2_USDHC2_DATA2		0x92	/* SD2_DATA2, SDIO_A_DATA2 */
				MX8MM_IOMUXC_SD2_DATA3_USDHC2_DATA3		0x92	/* SD2_DATA3, SDIO_A_DATA3 */
			>;
		};

		pinctrl_usdhc2_gpio: usdhc2grp-gpio {
			fsl,pins = <
				MX8MM_IOMUXC_SD2_CD_B_GPIO2_IO12		0x41	/* SD2_CD_B, SDIO_B_CD, linux-gpio-id=44 */
				MX8MM_IOMUXC_SD2_WP_GPIO2_IO20			0x41	/* SD2_WP, SDIO_B_WP,   linux-gpio-id=52 */
				MX8MM_IOMUXC_SD2_RESET_B_GPIO2_IO19		0x41	/* SDIO_B_PWR_EN,       linux-gpio-id=51 */
				MX8MM_IOMUXC_GPIO1_IO04_USDHC2_VSELECT		0x1d0	/* USDHC2_VSELECT			 */
			>;
		};

		pinctrl_usdhc2_100mhz: usdhc2grp-100mhz {
			fsl,pins = <
				MX8MM_IOMUXC_SD2_CLK_USDHC2_CLK			0x94	/* SD2_CLK,   SDIO_A_CK    */
				MX8MM_IOMUXC_SD2_CMD_USDHC2_CMD			0x94	/* SD2_CMD,   SDIO_A_CMD   */
				MX8MM_IOMUXC_SD2_DATA0_USDHC2_DATA0		0x94	/* SD2_DATA0, SDIO_A_DATA0 */
				MX8MM_IOMUXC_SD2_DATA1_USDHC2_DATA1		0x94	/* SD2_DATA1, SDIO_A_DATA1 */
				MX8MM_IOMUXC_SD2_DATA2_USDHC2_DATA2		0x94	/* SD2_DATA2, SDIO_A_DATA2 */
				MX8MM_IOMUXC_SD2_DATA3_USDHC2_DATA3		0x94	/* SD2_DATA3, SDIO_A_DATA3 */
			>;
		};

		pinctrl_usdhc2_200mhz: usdhc2grp-200mhz {
			fsl,pins = <
				MX8MM_IOMUXC_SD2_CLK_USDHC2_CLK			0x96	/* SD2_CLK,   SDIO_A_CK    */
				MX8MM_IOMUXC_SD2_CMD_USDHC2_CMD			0x96	/* SD2_CMD,   SDIO_A_CMD   */
				MX8MM_IOMUXC_SD2_DATA0_USDHC2_DATA0		0x96	/* SD2_DATA0, SDIO_A_DATA0 */
				MX8MM_IOMUXC_SD2_DATA1_USDHC2_DATA1		0x96	/* SD2_DATA1, SDIO_A_DATA1 */
				MX8MM_IOMUXC_SD2_DATA2_USDHC2_DATA2		0x96	/* SD2_DATA2, SDIO_A_DATA2 */
				MX8MM_IOMUXC_SD2_DATA3_USDHC2_DATA3		0x96	/* SD2_DATA3, SDIO_A_DATA3 */
			>;
		};

		/* emmc */
		pinctrl_usdhc3: usdhc3grp {
			fsl,pins = <
				MX8MM_IOMUXC_NAND_WE_B_USDHC3_CLK		0x40000190	/* EMMC_CK    */
				MX8MM_IOMUXC_NAND_WP_B_USDHC3_CMD		0x1d0		/* EMMC_CMD   */
				MX8MM_IOMUXC_NAND_DATA04_USDHC3_DATA0		0x1d0		/* EMMC_DATA0 */
				MX8MM_IOMUXC_NAND_DATA05_USDHC3_DATA1		0x1d0		/* EMMC_DATA1 */
				MX8MM_IOMUXC_NAND_DATA06_USDHC3_DATA2		0x1d0		/* EMMC_DATA2 */
				MX8MM_IOMUXC_NAND_DATA07_USDHC3_DATA3		0x1d0		/* EMMC_DATA3 */
				MX8MM_IOMUXC_NAND_RE_B_USDHC3_DATA4		0x1d0		/* EMMC_DATA4 */
				MX8MM_IOMUXC_NAND_CE2_B_USDHC3_DATA5		0x1d0		/* EMMC_DATA5 */
				MX8MM_IOMUXC_NAND_CE3_B_USDHC3_DATA6		0x1d0		/* EMMC_DATA6 */
				MX8MM_IOMUXC_NAND_CLE_USDHC3_DATA7		0x1d0		/* EMMC_DATA7 */
				MX8MM_IOMUXC_NAND_CE1_B_USDHC3_STROBE		0x190		/* EMMC_STRB  */
				MX8MM_IOMUXC_NAND_READY_B_GPIO3_IO16		0x116		/* EMMC_RST   */
			>;
		};

		pinctrl_usdhc3_100mhz: usdhc3grp-100mhz {
			fsl,pins = <
				MX8MM_IOMUXC_NAND_WE_B_USDHC3_CLK		0x40000194	/* EMMC_CK    */
				MX8MM_IOMUXC_NAND_WP_B_USDHC3_CMD		0x1d4		/* EMMC_CMD   */
				MX8MM_IOMUXC_NAND_DATA04_USDHC3_DATA0		0x1d4		/* EMMC_DATA0 */
				MX8MM_IOMUXC_NAND_DATA05_USDHC3_DATA1		0x1d4		/* EMMC_DATA1 */
				MX8MM_IOMUXC_NAND_DATA06_USDHC3_DATA2		0x1d4		/* EMMC_DATA2 */
				MX8MM_IOMUXC_NAND_DATA07_USDHC3_DATA3		0x1d4		/* EMMC_DATA3 */
				MX8MM_IOMUXC_NAND_RE_B_USDHC3_DATA4		0x1d4		/* EMMC_DATA4 */
				MX8MM_IOMUXC_NAND_CE2_B_USDHC3_DATA5		0x1d4		/* EMMC_DATA5 */
				MX8MM_IOMUXC_NAND_CE3_B_USDHC3_DATA6		0x1d4		/* EMMC_DATA6 */
				MX8MM_IOMUXC_NAND_CLE_USDHC3_DATA7		0x1d4		/* EMMC_DATA7 */
				MX8MM_IOMUXC_NAND_CE1_B_USDHC3_STROBE		0x194		/* EMMC_STRB  */
				MX8MM_IOMUXC_NAND_READY_B_GPIO3_IO16		0x116		/* EMMC_RST   */
			>;
		};

		pinctrl_usdhc3_200mhz: usdhc3grp-200mhz {
			fsl,pins = <
				MX8MM_IOMUXC_NAND_WE_B_USDHC3_CLK		0x40000196	/* EMMC_CK    */
				MX8MM_IOMUXC_NAND_WP_B_USDHC3_CMD		0x1d6		/* EMMC_CMD   */
				MX8MM_IOMUXC_NAND_DATA04_USDHC3_DATA0		0x1d6		/* EMMC_DATA0 */
				MX8MM_IOMUXC_NAND_DATA05_USDHC3_DATA1		0x1d6		/* EMMC_DATA1 */
				MX8MM_IOMUXC_NAND_DATA06_USDHC3_DATA2		0x1d6		/* EMMC_DATA2 */
				MX8MM_IOMUXC_NAND_DATA07_USDHC3_DATA3		0x1d6		/* EMMC_DATA3 */
				MX8MM_IOMUXC_NAND_RE_B_USDHC3_DATA4		0x1d6		/* EMMC_DATA4 */
				MX8MM_IOMUXC_NAND_CE2_B_USDHC3_DATA5		0x1d6		/* EMMC_DATA5 */
				MX8MM_IOMUXC_NAND_CE3_B_USDHC3_DATA6		0x1d6		/* EMMC_DATA6 */
				MX8MM_IOMUXC_NAND_CLE_USDHC3_DATA7		0x1d6		/* EMMC_DATA7 */
				MX8MM_IOMUXC_NAND_CE1_B_USDHC3_STROBE		0x196		/* EMMC_STRB  */
				MX8MM_IOMUXC_NAND_READY_B_GPIO3_IO16		0x116		/* EMMC_RST   */
			>;
		};

		pinctrl_usbotg1: usbotg1grp {
			fsl,pins = <
				MX8MM_IOMUXC_GPIO1_IO12_GPIO1_IO12	0x20		/* USB_A_PWR_EN */
				MX8MM_IOMUXC_GPIO1_IO13_USB1_OTG_OC	0x40000019	/* USB_A_OC     */
			>;
		};

		pinctrl_usbotg1_extcon: usbotg1extcongrp {
			fsl,pins = <
				MX8MM_IOMUXC_GPIO1_IO10_GPIO1_IO10	0x40000019	/* USB_A_ID */
			>;
		};

		pinctrl_usbotg2: usbotg2grp {
			fsl,pins = <
				MX8MM_IOMUXC_GPIO1_IO14_GPIO1_IO14	0x20		/* USB_B_PWR_EN */
				MX8MM_IOMUXC_GPIO1_IO15_USB2_OTG_OC	0x40000019	/* USB_B_OC */
			>;
		};

		pinctrl_flexspi: flexspi0grp {
			fsl,pins = <
				MX8MM_IOMUXC_NAND_ALE_QSPI_A_SCLK	0x1c6	/* QSPI_CK    */
				MX8MM_IOMUXC_NAND_CE0_B_QSPI_A_SS0_B	0x86	/* QSPI_CS0#  */
				MX8MM_IOMUXC_NAND_DATA00_QSPI_A_DATA0	0x86	/* QSPI_DATA0 */
				MX8MM_IOMUXC_NAND_DATA01_QSPI_A_DATA1	0x86	/* QSPI_DATA1 */
				MX8MM_IOMUXC_NAND_DATA02_QSPI_A_DATA2	0x86	/* QSPI_DATA2 */
				MX8MM_IOMUXC_NAND_DATA03_QSPI_A_DATA3	0x86	/* QSPI_DATA3 */
			>;
		};

		pinctrl_ecspi1: ecspi1grp {
			fsl,pins = <
				MX8MM_IOMUXC_ECSPI1_SCLK_ECSPI1_SCLK	0x82	/* SPI_A_CK */
				MX8MM_IOMUXC_ECSPI1_MOSI_ECSPI1_MOSI	0x82	/* SPI_A_MOSI */
				MX8MM_IOMUXC_ECSPI1_MISO_ECSPI1_MISO	0x82	/* SPI_A_MISO */
				MX8MM_IOMUXC_ECSPI1_SS0_GPIO5_IO9	0x19	/* SPI_A_CS#, linux-gpio-id=137 */
			>;
		};

		pinctrl_ecspi2: ecspi2grp {
			fsl,pins = <
				MX8MM_IOMUXC_ECSPI2_SCLK_ECSPI2_SCLK	0x82	/* SPI_B_CK   */
				MX8MM_IOMUXC_ECSPI2_MOSI_ECSPI2_MOSI	0x82	/* SPI_B_MOSI */
				MX8MM_IOMUXC_ECSPI2_MISO_ECSPI2_MISO	0x82	/* SPI_B_MISO */
				MX8MM_IOMUXC_ECSPI2_SS0_GPIO5_IO13	0x19	/* SPI_B_CS0, linux-gpio-id=141 */
			>;
		};

		pinctrl_sai5: sai5grp {
			fsl,pins = <
				MX8MM_IOMUXC_SAI5_RXD0_SAI5_RX_DATA0	0xd6	/* I2S0_SDIN */
				MX8MM_IOMUXC_SAI5_RXD1_SAI5_TX_SYNC	0xd6	/* I2S0_LRCK */
				MX8MM_IOMUXC_SAI5_RXD2_SAI5_TX_BCLK	0xd6	/* I2S0_BCLK */
				MX8MM_IOMUXC_SAI5_RXD3_SAI5_TX_DATA0	0xd6	/* I2S0_SDOUT */
			>;
		};

		pinctrl_rtc1: rtc1grp {
			fsl,pins = <
				MX8MM_IOMUXC_SAI5_RXFS_GPIO3_IO19	0x19	/* RTC_INT#, linux-gpio-id=83 */
			>;
		};

		pinctrl_wdog1: wdog1grp {
			fsl,pins = <
				/* WDOG1, WDT_TIME_OUT */
				MX8MM_IOMUXC_GPIO1_IO02_WDOG1_WDOG_B	0xc6
			>;
		};

		pinctrl_pwm1: pwm1grp {
			fsl,pins = <
				MX8MM_IOMUXC_SPDIF_EXT_CLK_PWM1_OUT	0x19	/* PWM_0 */
			>;
		};

		pinctrl_pwm2: pwm2grp {
			fsl,pins = <
				MX8MM_IOMUXC_SPDIF_RX_PWM2_OUT		0x19	/* PWM_1 */
			>;
		};

		pinctrl_pwm3: pwm3grp {
			fsl,pins = <
				 MX8MM_IOMUXC_SPDIF_TX_PWM3_OUT		0x19	/* PWM_2 */
			>;
		};

		pinctrl_pwm4: pwm4grp {
			fsl,pins = <
				MX8MM_IOMUXC_SAI3_MCLK_PWM4_OUT		0x19	/* PWM_3 */
			>;
		};

		pinctrl_pcie: pciegrp {
			fsl,pins = <
				MX8MM_IOMUXC_SAI1_RXC_GPIO4_IO1		0x19		/* PCIE_A_RST,    linux-gpio-id= 97 */
				MX8MM_IOMUXC_SAI1_TXFS_GPIO4_IO10	0x40000019	/* PCIE_SM_ALERT, linux-gpio-id=106 */
				MX8MM_IOMUXC_SD1_STROBE_GPIO2_IO11	0x40000019	/* PCIE_WAKE#,    linux-gpio-id= 43 */
				MX8MM_IOMUXC_SAI1_RXFS_GPIO4_IO0	0x40000098	/* PCIE_CLKREQ */
			>;
		};

		pinctrl_leds: ledgrp {
			fsl,pins = <
				MX8MM_IOMUXC_SAI2_MCLK_GPIO4_IO27		0x19	/* DEBUG_LED*/
			>;
		};
	};
};
